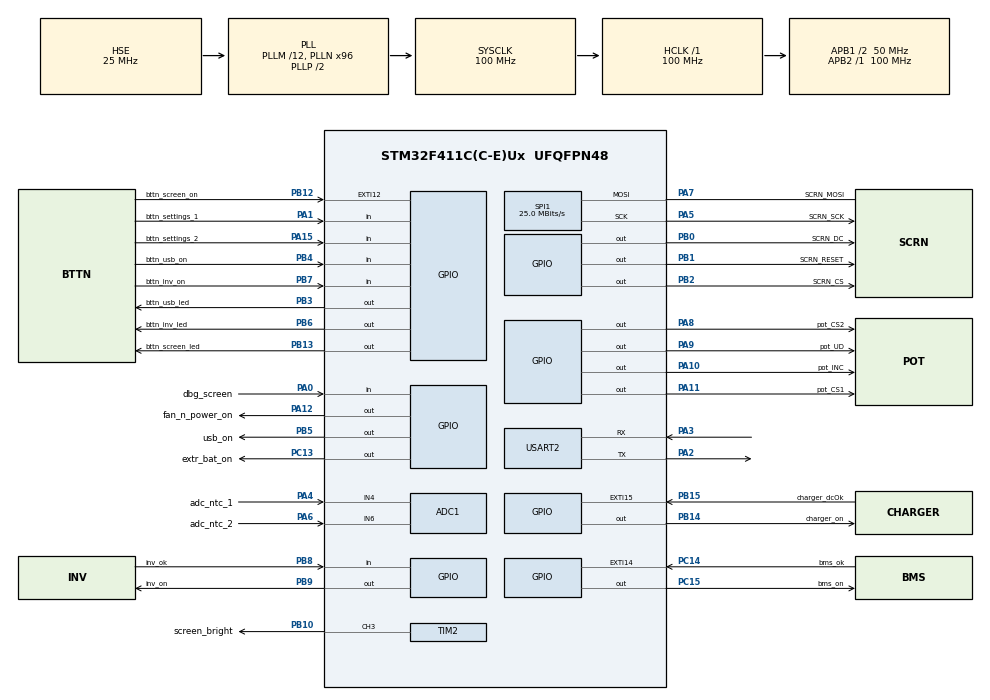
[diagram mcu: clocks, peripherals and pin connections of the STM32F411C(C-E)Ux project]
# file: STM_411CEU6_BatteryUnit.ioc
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ADC1.Channel-0\#ChannelRegularConversion=ADC_CHANNEL_4
ADC1.NbrOfConversionFlag=1
ADC1.Rank-0\#ChannelRegularConversion=1
ADC1.SamplingTime-0\#ChannelRegularConversion=ADC_SAMPLETIME_3CYCLES
ADC1.master=1
Dma.Request0=SPI1_TX
Dma.SPI1_TX.0.Direction=DMA_MEMORY_TO_PERIPH
Dma.SPI1_TX.0.FIFOMode=DMA_FIFOMODE_ENABLE
Dma.SPI1_TX.0.FIFOThreshold=DMA_FIFO_THRESHOLD_FULL
Dma.SPI1_TX.0.Instance=DMA2_Stream2
Dma.SPI1_TX.0.MemBurst=DMA_MBURST_SINGLE
Dma.SPI1_TX.0.MemDataAlignment=DMA_MDATAALIGN_BYTE
Dma.SPI1_TX.0.MemInc=DMA_MINC_ENABLE
Dma.SPI1_TX.0.Mode=DMA_NORMAL
Dma.SPI1_TX.0.PeriphBurst=DMA_PBURST_SINGLE
Dma.SPI1_TX.0.PeriphDataAlignment=DMA_PDATAALIGN_BYTE
Dma.SPI1_TX.0.PeriphInc=DMA_PINC_DISABLE
Dma.SPI1_TX.0.Priority=DMA_PRIORITY_MEDIUM
FREERTOS.Tasks01=defaultTask,24,1024,StartDefaultTask,Default,NULL,Dynamic,NULL,NULL;GUI_Task,24,2560,StartGUITask,Default,NULL,Dynamic,NULL,NULL
FREERTOS.configUSE_NEWLIB_REENTRANT=1
FREERTOS.configUSE_TICKLESS_IDLE=1
Mcu.Family=STM32F4
Mcu.Name=STM32F411C(C-E)Ux
Mcu.Package=UFQFPN48
NVIC.DMA2_Stream2_IRQn=true\:5\:0\:true\:false\:true\:true\:false\:true\:true
NVIC.EXTI15_10_IRQn=true\:5\:0\:false\:false\:true\:true\:true\:true\:true
NVIC.PriorityGroup=NVIC_PRIORITYGROUP_4
NVIC.RCC_IRQn=true\:5\:0\:true\:false\:true\:true\:true\:false\:true
NVIC.RTC_Alarm_IRQn=true\:5\:0\:false\:false\:true\:true\:true\:true\:true
NVIC.SPI1_IRQn=true\:5\:0\:false\:false\:true\:true\:true\:true\:true
NVIC.TIM1_UP_TIM10_IRQn=true\:15\:0\:false\:false\:true\:false\:false\:true\:true
NVIC.TIM4_IRQn=true\:5\:0\:false\:false\:true\:true\:true\:true\:true
NVIC.TimeBase=TIM1_UP_TIM10_IRQn
NVIC.TimeBaseIP=TIM1
NVIC.USART2_IRQn=true\:2\:0\:true\:false\:true\:false\:true\:true\:true
PA0-WKUP.GPIO_Label=dbg_screen
PA0-WKUP.GPIO_PuPd=GPIO_PULLUP
PA0-WKUP.Signal=GPIO_Input
PA1.GPIO_Label=bttn_settings_1
PA1.GPIO_PuPd=GPIO_PULLUP
PA1.Signal=GPIO_Input
PA10.GPIO_Label=pot_INC
PA10.GPIO_ModeDefaultOutputPP=GPIO_MODE_OUTPUT_PP
PA10.GPIO_PuPd=GPIO_PULLDOWN
PA10.PinState=GPIO_PIN_SET
PA10.Signal=GPIO_Output
PA11.GPIO_Label=pot_CS1
PA11.GPIO_PuPd=GPIO_PULLDOWN
PA11.GPIO_Speed=GPIO_SPEED_FREQ_MEDIUM
PA11.PinState=GPIO_PIN_SET
PA11.Signal=GPIO_Output
PA12.GPIO_Label=fan_n_power_on
PA12.GPIO_PuPd=GPIO_PULLDOWN
PA12.Signal=GPIO_Output
PA13.Mode=Serial_Wire
PA13.Signal=SYS_JTMS-SWDIO
PA14.Mode=Serial_Wire
PA14.Signal=SYS_JTCK-SWCLK
PA15.GPIO_Label=bttn_settings_2
PA15.GPIO_PuPd=GPIO_PULLUP
PA15.Signal=GPIO_Input
PA2.Mode=Asynchronous
PA2.Signal=USART2_TX
PA3.Mode=Asynchronous
PA3.Signal=USART2_RX
PA4.GPIO_Label=adc_ntc_1
PA4.Signal=ADCx_IN4
PA5.GPIO_Label=SCRN_SCK
PA5.Mode=Simplex_Bidirectional_Master
PA5.Signal=SPI1_SCK
PA6.GPIO_Label=adc_ntc_2
PA6.Signal=ADCx_IN6
PA7.GPIO_Label=SCRN_MOSI
PA7.Mode=Simplex_Bidirectional_Master
PA7.Signal=SPI1_MOSI
PA8.GPIO_Label=pot_CS2
PA8.GPIO_PuPd=GPIO_PULLDOWN
PA8.GPIO_Speed=GPIO_SPEED_FREQ_MEDIUM
PA8.PinState=GPIO_PIN_SET
PA8.Signal=GPIO_Output
PA9.GPIO_Label=pot_UD
PA9.GPIO_PuPd=GPIO_PULLDOWN
PA9.GPIO_Speed=GPIO_SPEED_FREQ_MEDIUM
PA9.Signal=GPIO_Output
PB0.GPIO_Label=SCRN_DC
PB0.GPIO_PuPd=GPIO_PULLDOWN
PB0.GPIO_Speed=GPIO_SPEED_FREQ_HIGH
PB0.Signal=GPIO_Output
PB1.GPIO_Label=SCRN_RESET
PB1.GPIO_PuPd=GPIO_PULLDOWN
PB1.GPIO_Speed=GPIO_SPEED_FREQ_HIGH
PB1.Signal=GPIO_Output
PB10.GPIO_Label=screen_bright
PB10.Signal=S_TIM2_CH3
PB12.GPIO_Label=bttn_screen_on
PB12.GPIO_PuPd=GPIO_PULLUP
PB12.Signal=GPXTI12
PB13.GPIO_Label=bttn_screen_led
PB13.GPIO_PuPd=GPIO_PULLDOWN
PB13.Signal=GPIO_Output
PB14.GPIO_Label=charger_on
PB14.GPIO_PuPd=GPIO_PULLUP
PB14.PinState=GPIO_PIN_SET
PB14.Signal=GPIO_Output
PB15.GPIO_Label=charger_dcOk
PB15.GPIO_ModeDefaultEXTI=GPIO_MODE_IT_FALLING
PB15.GPIO_PuPd=GPIO_PULLUP
PB15.Signal=GPXTI15
PB2.GPIO_Label=SCRN_CS
PB2.GPIO_PuPd=GPIO_PULLDOWN
PB2.GPIO_Speed=GPIO_SPEED_FREQ_HIGH
PB2.Signal=GPIO_Output
PB3.GPIO_Label=bttn_usb_led
PB3.GPIO_PuPd=GPIO_PULLDOWN
PB3.Signal=GPIO_Output
PB4.GPIO_Label=bttn_usb_on
PB4.GPIO_PuPd=GPIO_PULLUP
PB4.Signal=GPIO_Input
PB5.GPIO_Label=usb_on
PB5.GPIO_PuPd=GPIO_PULLDOWN
PB5.Signal=GPIO_Output
PB6.GPIO_Label=bttn_inv_led
PB6.GPIO_PuPd=GPIO_PULLDOWN
PB6.Signal=GPIO_Output
PB7.GPIO_Label=bttn_inv_on
PB7.GPIO_PuPd=GPIO_PULLUP
PB7.Signal=GPIO_Input
PB8.GPIO_Label=inv_ok
PB8.GPIO_PuPd=GPIO_PULLDOWN
PB8.Signal=GPIO_Input
PB9.GPIO_Label=inv_on
PB9.GPIO_PuPd=GPIO_PULLDOWN
PB9.Signal=GPIO_Output
PC13-ANTI_TAMP.GPIO_Label=extr_bat_on
PC13-ANTI_TAMP.PinState=GPIO_PIN_SET
PC13-ANTI_TAMP.Signal=GPIO_Output
PC14-OSC32_IN.GPIO_Label=bms_ok
PC14-OSC32_IN.GPIO_ModeDefaultEXTI=GPIO_MODE_IT_FALLING
PC14-OSC32_IN.GPIO_PuPd=GPIO_PULLUP
PC14-OSC32_IN.Signal=GPXTI14
PC15-OSC32_OUT.GPIO_Label=bms_on
PC15-OSC32_OUT.GPIO_PuPd=GPIO_PULLDOWN
PC15-OSC32_OUT.Signal=GPIO_Output
PH0\ -\ OSC_IN.Mode=HSE-External-Oscillator
PH0\ -\ OSC_IN.Signal=RCC_OSC_IN
PH1\ -\ OSC_OUT.Mode=HSE-External-Oscillator
PH1\ -\ OSC_OUT.Signal=RCC_OSC_OUT
ProjectManager.HeapSize=0x200
ProjectManager.StackSize=0x400
ProjectManager.TargetToolchain=STM32CubeIDE
RCC.48MHZClocksFreq_Value=50000000
RCC.AHBFreq_Value=100000000
RCC.APB1CLKDivider=RCC_HCLK_DIV2
RCC.APB1Freq_Value=50000000
RCC.APB1TimFreq_Value=100000000
RCC.APB2Freq_Value=100000000
RCC.APB2TimFreq_Value=100000000
RCC.CortexFreq_Value=100000000
RCC.HCLKFreq_Value=100000000
RCC.HSE_Timout=60000
RCC.HSE_VALUE=25000000
RCC.HSI_VALUE=16000000
RCC.LSE_VALUE=32768
RCC.PLLM=12
RCC.PLLN=96
RCC.PLLSourceVirtual=RCC_PLLSOURCE_HSE
RCC.RCC_RTC_Clock_Source=RCC_RTCCLKSOURCE_LSI
RCC.RCC_RTC_Clock_SourceVirtual=RCC_RTCCLKSOURCE_LSI
RCC.SYSCLKFreq_VALUE=100000000
RCC.SYSCLKSource=RCC_SYSCLKSOURCE_PLLCLK
RCC.VCOOutputFreq_Value=200000000
RTC.Alarm=RTC_ALARM_A
RTC.AlarmDateWeekDay=22
RTC.Date=22
RTC.Format=RTC_FORMAT_BIN
RTC.Hours=0
RTC.Hours_A=0
RTC.Minutes=0
RTC.Minutes_A=0
RTC.Month=RTC_MONTH_APRIL
RTC.Seconds=0
RTC.Seconds_A=20
RTC.Year=24
SH.ADCx_IN4.0=ADC1_IN4,IN4
SH.ADCx_IN6.0=ADC1_IN6,IN6
SH.S_TIM2_CH3.0=TIM2_CH3,PWM Generation3 CH3
SPI1.BaudRatePrescaler=SPI_BAUDRATEPRESCALER_4
SPI1.CRCCalculation=SPI_CRCCALCULATION_DISABLE
SPI1.CalculateBaudRate=25.0 MBits/s
SPI1.Direction=SPI_DIRECTION_1LINE
SPI1.Mode=SPI_MODE_MASTER
SPI1.VirtualType=VM_MASTER
STMicroelectronics.X-CUBE-TOUCHGFX.4.24.1.ApplicationCcGraphicsJjApplication=TouchGFXOoGenerator
STMicroelectronics.X-CUBE-TOUCHGFX.4.24.1.tgfx_block_size=1920
STMicroelectronics.X-CUBE-TOUCHGFX.4.24.1.tgfx_buffering_strategy=Partial
STMicroelectronics.X-CUBE-TOUCHGFX.4.24.1.tgfx_custom_height=240
STMicroelectronics.X-CUBE-TOUCHGFX.4.24.1.tgfx_custom_width=320
STMicroelectronics.X-CUBE-TOUCHGFX.4.24.1.tgfx_oswrapper=CMSIS V2
STMicroelectronics.X-CUBE-TOUCHGFX.4.24.1_IsPackSelfContextualization=true
TIM2.Channel-PWM\ Generation3\ CH3=TIM_CHANNEL_3
TIM2.Period=999
TIM2.Prescaler=99
TIM4.Period=15
TIM4.Prescaler=44999
USART2.VirtualMode=VM_ASYNC
VP_CRC_VS_CRC.Mode=CRC_Activate
VP_FREERTOS_VS_CMSIS_V2.Mode=CMSIS_V2
VP_RTC_VS_RTC_Activate.Mode=RTC_Enabled
VP_RTC_VS_RTC_Alarm_A_Intern.Mode=Alarm A
VP_RTC_VS_RTC_Calendar.Mode=RTC_Calendar
VP_STMicroelectronics.X-CUBE-TOUCHGFX_VS_GraphicsJjApplication_4.24.1.Mode=GraphicsJjApplication
VP_SYS_VS_tim1.Mode=TIM1
VP_TIM2_VS_ClockSourceINT.Mode=Internal
VP_TIM4_VS_ClockSourceINT.Mode=Internal
board=custom

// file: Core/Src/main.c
/* USER CODE BEGIN Header */
/**
  ******************************************************************************
  * @file           : main.c
  * @brief          : Main program body
  ******************************************************************************
  * @attention
  *
  * Copyright (c) 2024 STMicroelectronics.
  * All rights reserved.
  *
  * This software is licensed under terms that can be found in the LICENSE file
  * in the root directory of this software component.
  * If no LICENSE file comes with this software, it is provided AS-IS.
  *
  ******************************************************************************
  */
/* USER CODE END Header */
#include "main.h"
#include "cmsis_os.h"
#include "app_touchgfx.h"

/* USER CODE BEGIN Includes */
#include <program.h>
/* USER CODE END Includes */

ADC_HandleTypeDef hadc1;

CRC_HandleTypeDef hcrc;

RTC_HandleTypeDef hrtc;

SPI_HandleTypeDef hspi1;
DMA_HandleTypeDef hdma_spi1_tx;

TIM_HandleTypeDef htim2;
TIM_HandleTypeDef htim4;

UART_HandleTypeDef huart2;

/* Definitions for defaultTask */
osThreadId_t defaultTaskHandle;
const osThreadAttr_t defaultTask_attributes = {
  .name = "defaultTask",
  .stack_size = 1024 * 4,
  .priority = (osPriority_t) osPriorityNormal,
};
/* Definitions for GUI_Task */
osThreadId_t GUI_TaskHandle;
const osThreadAttr_t GUI_Task_attributes = {
  .name = "GUI_Task",
  .stack_size = 2560 * 4,
  .priority = (osPriority_t) osPriorityNormal,
};

void SystemClock_Config(void);
static void MX_GPIO_Init(void);
static void MX_DMA_Init(void);
static void MX_SPI1_Init(void);
static void MX_CRC_Init(void);
static void MX_TIM4_Init(void);
static void MX_USART2_UART_Init(void);
static void MX_RTC_Init(void);
static void MX_TIM2_Init(void);
static void MX_ADC1_Init(void);
void StartDefaultTask(void *argument);
void StartGUITask(void *argument);

int main(void)
{

  /* MCU Configuration--------------------------------------------------------*/

  /* Reset of all peripherals, Initializes the Flash interface and the Systick. */
  HAL_Init();

  /* Configure the system clock */
  SystemClock_Config();

  /* Initialize all configured peripherals */
  MX_GPIO_Init();
  MX_DMA_Init();
  MX_SPI1_Init();
  MX_CRC_Init();
  MX_TIM4_Init();
  MX_USART2_UART_Init();
  MX_RTC_Init();
  MX_TIM2_Init();
  MX_ADC1_Init();
  MX_TouchGFX_Init();
  /* Call PreOsInit function */
  MX_TouchGFX_PreOSInit();
  /* USER CODE BEGIN 2 */
//  Program_Process();
  /* USER CODE END 2 */

  /* Init scheduler */
  osKernelInitialize();

  /* Create the thread(s) */
  /* creation of defaultTask */
  defaultTaskHandle = osThreadNew(StartDefaultTask, NULL, &defaultTask_attributes);

  /* creation of GUI_Task */
  GUI_TaskHandle = osThreadNew(StartGUITask, NULL, &GUI_Task_attributes);

  /* Start scheduler */
  osKernelStart();

  /* We should never get here as control is now taken by the scheduler */

  /* Infinite loop */
  while (1)
  {

  }
}

void SystemClock_Config(void)
{
  RCC_OscInitTypeDef RCC_OscInitStruct = {0};
  RCC_ClkInitTypeDef RCC_ClkInitStruct = {0};

  /** Configure the main internal regulator output voltage
  */
  __HAL_RCC_PWR_CLK_ENABLE();
  __HAL_PWR_VOLTAGESCALING_CONFIG(PWR_REGULATOR_VOLTAGE_SCALE1);

  /** Initializes the RCC Oscillators according to the specified parameters
  * in the RCC_OscInitTypeDef structure.
  */
  RCC_OscInitStruct.OscillatorType = RCC_OSCILLATORTYPE_LSI|RCC_OSCILLATORTYPE_HSE;
  RCC_OscInitStruct.HSEState = RCC_HSE_ON;
  RCC_OscInitStruct.LSIState = RCC_LSI_ON;
  RCC_OscInitStruct.PLL.PLLState = RCC_PLL_ON;
  RCC_OscInitStruct.PLL.PLLSource = RCC_PLLSOURCE_HSE;
  RCC_OscInitStruct.PLL.PLLM = 12;
  RCC_OscInitStruct.PLL.PLLN = 96;
  RCC_OscInitStruct.PLL.PLLP = RCC_PLLP_DIV2;
  RCC_OscInitStruct.PLL.PLLQ = 4;
  if (HAL_RCC_OscConfig(&RCC_OscInitStruct) != HAL_OK)
  {
    Error_Handler();
  }

  /** Initializes the CPU, AHB and APB buses clocks
  */
  RCC_ClkInitStruct.ClockType = RCC_CLOCKTYPE_HCLK|RCC_CLOCKTYPE_SYSCLK
                              |RCC_CLOCKTYPE_PCLK1|RCC_CLOCKTYPE_PCLK2;
  RCC_ClkInitStruct.SYSCLKSource = RCC_SYSCLKSOURCE_PLLCLK;
  RCC_ClkInitStruct.AHBCLKDivider = RCC_SYSCLK_DIV1;
  RCC_ClkInitStruct.APB1CLKDivider = RCC_HCLK_DIV2;
  RCC_ClkInitStruct.APB2CLKDivider = RCC_HCLK_DIV1;

  if (HAL_RCC_ClockConfig(&RCC_ClkInitStruct, FLASH_LATENCY_3) != HAL_OK)
  {
    Error_Handler();
  }
}

static void MX_ADC1_Init(void)
{

  ADC_ChannelConfTypeDef sConfig = {0};

  /** Configure the global features of the ADC (Clock, Resolution, Data Alignment and number of conversion)
  */
  hadc1.Instance = ADC1;
  hadc1.Init.ClockPrescaler = ADC_CLOCK_SYNC_PCLK_DIV4;
  hadc1.Init.Resolution = ADC_RESOLUTION_12B;
  hadc1.Init.ScanConvMode = DISABLE;
  hadc1.Init.ContinuousConvMode = DISABLE;
  hadc1.Init.DiscontinuousConvMode = DISABLE;
  hadc1.Init.ExternalTrigConvEdge = ADC_EXTERNALTRIGCONVEDGE_NONE;
  hadc1.Init.ExternalTrigConv = ADC_SOFTWARE_START;
  hadc1.Init.DataAlign = ADC_DATAALIGN_RIGHT;
  hadc1.Init.NbrOfConversion = 1;
  hadc1.Init.DMAContinuousRequests = DISABLE;
  hadc1.Init.EOCSelection = ADC_EOC_SINGLE_CONV;
  if (HAL_ADC_Init(&hadc1) != HAL_OK)
  {
    Error_Handler();
  }

  /** Configure for the selected ADC regular channel its corresponding rank in the sequencer and its sample time.
  */
  sConfig.Channel = ADC_CHANNEL_4;
  sConfig.Rank = 1;
  sConfig.SamplingTime = ADC_SAMPLETIME_3CYCLES;
  if (HAL_ADC_ConfigChannel(&hadc1, &sConfig) != HAL_OK)
  {
    Error_Handler();
  }

}

static void MX_CRC_Init(void)
{

  hcrc.Instance = CRC;
  if (HAL_CRC_Init(&hcrc) != HAL_OK)
  {
    Error_Handler();
  }

}

static void MX_RTC_Init(void)
{

  RTC_TimeTypeDef sTime = {0};
  RTC_DateTypeDef sDate = {0};
  RTC_AlarmTypeDef sAlarm = {0};

  /** Initialize RTC Only
  */
  hrtc.Instance = RTC;
  hrtc.Init.HourFormat = RTC_HOURFORMAT_24;
  hrtc.Init.AsynchPrediv = 127;
  hrtc.Init.SynchPrediv = 255;
  hrtc.Init.OutPut = RTC_OUTPUT_DISABLE;
  hrtc.Init.OutPutPolarity = RTC_OUTPUT_POLARITY_HIGH;
  hrtc.Init.OutPutType = RTC_OUTPUT_TYPE_OPENDRAIN;
  if (HAL_RTC_Init(&hrtc) != HAL_OK)
  {
    Error_Handler();
  }

  /* USER CODE BEGIN Check_RTC_BKUP */
  if (Check_RTC_Backup(&hrtc)) {
	  return;
  }
  /* USER CODE END Check_RTC_BKUP */

  /** Initialize RTC and set the Time and Date
  */
  sTime.Hours = 0;
  sTime.Minutes = 0;
  sTime.Seconds = 0;
  sTime.DayLightSaving = RTC_DAYLIGHTSAVING_NONE;
  sTime.StoreOperation = RTC_STOREOPERATION_RESET;
  if (HAL_RTC_SetTime(&hrtc, &sTime, RTC_FORMAT_BIN) != HAL_OK)
  {
    Error_Handler();
  }
  sDate.WeekDay = RTC_WEEKDAY_MONDAY;
  sDate.Month = RTC_MONTH_APRIL;
  sDate.Date = 22;
  sDate.Year = 24;

  if (HAL_RTC_SetDate(&hrtc, &sDate, RTC_FORMAT_BIN) != HAL_OK)
  {
    Error_Handler();
  }

  /** Enable the Alarm A
  */
  sAlarm.AlarmTime.Hours = 0;
  sAlarm.AlarmTime.Minutes = 0;
  sAlarm.AlarmTime.Seconds = 20;
  sAlarm.AlarmTime.SubSeconds = 0;
  sAlarm.AlarmTime.DayLightSaving = RTC_DAYLIGHTSAVING_NONE;
  sAlarm.AlarmTime.StoreOperation = RTC_STOREOPERATION_RESET;
  sAlarm.AlarmMask = RTC_ALARMMASK_NONE;
  sAlarm.AlarmSubSecondMask = RTC_ALARMSUBSECONDMASK_ALL;
  sAlarm.AlarmDateWeekDaySel = RTC_ALARMDATEWEEKDAYSEL_DATE;
  sAlarm.AlarmDateWeekDay = 22;
  sAlarm.Alarm = RTC_ALARM_A;
  if (HAL_RTC_SetAlarm_IT(&hrtc, &sAlarm, RTC_FORMAT_BIN) != HAL_OK)
  {
    Error_Handler();
  }
  /* USER CODE BEGIN RTC_Init 2 */
  RTC_Backup(&hrtc, &sAlarm);
  /* USER CODE END RTC_Init 2 */

}

static void MX_SPI1_Init(void)
{

  /* SPI1 parameter configuration*/
  hspi1.Instance = SPI1;
  hspi1.Init.Mode = SPI_MODE_MASTER;
  hspi1.Init.Direction = SPI_DIRECTION_1LINE;
  hspi1.Init.DataSize = SPI_DATASIZE_8BIT;
  hspi1.Init.CLKPolarity = SPI_POLARITY_LOW;
  hspi1.Init.CLKPhase = SPI_PHASE_1EDGE;
  hspi1.Init.NSS = SPI_NSS_SOFT;
  hspi1.Init.BaudRatePrescaler = SPI_BAUDRATEPRESCALER_4;
  hspi1.Init.FirstBit = SPI_FIRSTBIT_MSB;
  hspi1.Init.TIMode = SPI_TIMODE_DISABLE;
  hspi1.Init.CRCCalculation = SPI_CRCCALCULATION_DISABLE;
  hspi1.Init.CRCPolynomial = 10;
  if (HAL_SPI_Init(&hspi1) != HAL_OK)
  {
    Error_Handler();
  }

}

static void MX_TIM2_Init(void)
{

  TIM_ClockConfigTypeDef sClockSourceConfig = {0};
  TIM_MasterConfigTypeDef sMasterConfig = {0};
  TIM_OC_InitTypeDef sConfigOC = {0};

  htim2.Instance = TIM2;
  htim2.Init.Prescaler = 99;
  htim2.Init.CounterMode = TIM_COUNTERMODE_UP;
  htim2.Init.Period = 999;
  htim2.Init.ClockDivision = TIM_CLOCKDIVISION_DIV1;
  htim2.Init.AutoReloadPreload = TIM_AUTORELOAD_PRELOAD_DISABLE;
  if (HAL_TIM_Base_Init(&htim2) != HAL_OK)
  {
    Error_Handler();
  }
  sClockSourceConfig.ClockSource = TIM_CLOCKSOURCE_INTERNAL;
  if (HAL_TIM_ConfigClockSource(&htim2, &sClockSourceConfig) != HAL_OK)
  {
    Error_Handler();
  }
  if (HAL_TIM_PWM_Init(&htim2) != HAL_OK)
  {
    Error_Handler();
  }
  sMasterConfig.MasterOutputTrigger = TIM_TRGO_RESET;
  sMasterConfig.MasterSlaveMode = TIM_MASTERSLAVEMODE_DISABLE;
  if (HAL_TIMEx_MasterConfigSynchronization(&htim2, &sMasterConfig) != HAL_OK)
  {
    Error_Handler();
  }
  sConfigOC.OCMode = TIM_OCMODE_PWM1;
  sConfigOC.Pulse = 0;
  sConfigOC.OCPolarity = TIM_OCPOLARITY_HIGH;
  sConfigOC.OCFastMode = TIM_OCFAST_DISABLE;
  if (HAL_TIM_PWM_ConfigChannel(&htim2, &sConfigOC, TIM_CHANNEL_3) != HAL_OK)
  {
    Error_Handler();
  }
  HAL_TIM_MspPostInit(&htim2);

}

static void MX_TIM4_Init(void)
{

  TIM_ClockConfigTypeDef sClockSourceConfig = {0};
  TIM_MasterConfigTypeDef sMasterConfig = {0};

  htim4.Instance = TIM4;
  htim4.Init.Prescaler = 44999;
  htim4.Init.CounterMode = TIM_COUNTERMODE_UP;
  htim4.Init.Period = 15;
  htim4.Init.ClockDivision = TIM_CLOCKDIVISION_DIV1;
  htim4.Init.AutoReloadPreload = TIM_AUTORELOAD_PRELOAD_DISABLE;
  if (HAL_TIM_Base_Init(&htim4) != HAL_OK)
  {
    Error_Handler();
  }
  sClockSourceConfig.ClockSource = TIM_CLOCKSOURCE_INTERNAL;
  if (HAL_TIM_ConfigClockSource(&htim4, &sClockSourceConfig) != HAL_OK)
  {
    Error_Handler();
  }
  sMasterConfig.MasterOutputTrigger = TIM_TRGO_RESET;
  sMasterConfig.MasterSlaveMode = TIM_MASTERSLAVEMODE_DISABLE;
  if (HAL_TIMEx_MasterConfigSynchronization(&htim4, &sMasterConfig) != HAL_OK)
  {
    Error_Handler();
  }

}

static void MX_USART2_UART_Init(void)
{

  huart2.Instance = USART2;
  huart2.Init.BaudRate = 115200;
  huart2.Init.WordLength = UART_WORDLENGTH_8B;
  huart2.Init.StopBits = UART_STOPBITS_1;
  huart2.Init.Parity = UART_PARITY_NONE;
  huart2.Init.Mode = UART_MODE_TX_RX;
  huart2.Init.HwFlowCtl = UART_HWCONTROL_NONE;
  huart2.Init.OverSampling = UART_OVERSAMPLING_16;
  if (HAL_UART_Init(&huart2) != HAL_OK)
  {
    Error_Handler();
  }

}

static void MX_DMA_Init(void)
{

  /* DMA controller clock enable */
  __HAL_RCC_DMA2_CLK_ENABLE();

  /* DMA interrupt init */
  /* DMA2_Stream2_IRQn interrupt configuration */
  HAL_NVIC_SetPriority(DMA2_Stream2_IRQn, 5, 0);
  HAL_NVIC_EnableIRQ(DMA2_Stream2_IRQn);

}

static void MX_GPIO_Init(void)
{
  GPIO_InitTypeDef GPIO_InitStruct = {0};

  /* GPIO Ports Clock Enable */
  __HAL_RCC_GPIOC_CLK_ENABLE();
  __HAL_RCC_GPIOH_CLK_ENABLE();
  __HAL_RCC_GPIOA_CLK_ENABLE();
  __HAL_RCC_GPIOB_CLK_ENABLE();

  /*Configure GPIO pin Output Level */
  HAL_GPIO_WritePin(extr_bat_on_GPIO_Port, extr_bat_on_Pin, GPIO_PIN_SET);

  /*Configure GPIO pin Output Level */
  HAL_GPIO_WritePin(bms_on_GPIO_Port, bms_on_Pin, GPIO_PIN_RESET);

  /*Configure GPIO pin Output Level */
  HAL_GPIO_WritePin(GPIOB, SCRN_DC_Pin|SCRN_RESET_Pin|SCRN_CS_Pin|bttn_screen_led_Pin
                          |bttn_usb_led_Pin|usb_on_Pin|bttn_inv_led_Pin|inv_on_Pin, GPIO_PIN_RESET);

  /*Configure GPIO pin Output Level */
  HAL_GPIO_WritePin(charger_on_GPIO_Port, charger_on_Pin, GPIO_PIN_SET);

  /*Configure GPIO pin Output Level */
  HAL_GPIO_WritePin(GPIOA, pot_CS2_Pin|pot_INC_Pin|pot_CS1_Pin, GPIO_PIN_SET);

  /*Configure GPIO pin Output Level */
  HAL_GPIO_WritePin(GPIOA, pot_UD_Pin|fan_n_power_on_Pin, GPIO_PIN_RESET);

  /*Configure GPIO pin : extr_bat_on_Pin */
  GPIO_InitStruct.Pin = extr_bat_on_Pin;
  GPIO_InitStruct.Mode = GPIO_MODE_OUTPUT_PP;
  GPIO_InitStruct.Pull = GPIO_NOPULL;
  GPIO_InitStruct.Speed = GPIO_SPEED_FREQ_LOW;
  HAL_GPIO_Init(extr_bat_on_GPIO_Port, &GPIO_InitStruct);

  /*Configure GPIO pin : bms_ok_Pin */
  GPIO_InitStruct.Pin = bms_ok_Pin;
  GPIO_InitStruct.Mode = GPIO_MODE_IT_FALLING;
  GPIO_InitStruct.Pull = GPIO_PULLUP;
  HAL_GPIO_Init(bms_ok_GPIO_Port, &GPIO_InitStruct);

  /*Configure GPIO pin : bms_on_Pin */
  GPIO_InitStruct.Pin = bms_on_Pin;
  GPIO_InitStruct.Mode = GPIO_MODE_OUTPUT_PP;
  GPIO_InitStruct.Pull = GPIO_PULLDOWN;
  GPIO_InitStruct.Speed = GPIO_SPEED_FREQ_LOW;
  HAL_GPIO_Init(bms_on_GPIO_Port, &GPIO_InitStruct);

  /*Configure GPIO pins : dbg_screen_Pin bttn_settings_1_Pin bttn_settings_2_Pin */
  GPIO_InitStruct.Pin = dbg_screen_Pin|bttn_settings_1_Pin|bttn_settings_2_Pin;
  GPIO_InitStruct.Mode = GPIO_MODE_INPUT;
  GPIO_InitStruct.Pull = GPIO_PULLUP;
  HAL_GPIO_Init(GPIOA, &GPIO_InitStruct);

  /*Configure GPIO pins : SCRN_DC_Pin SCRN_RESET_Pin SCRN_CS_Pin */
  GPIO_InitStruct.Pin = SCRN_DC_Pin|SCRN_RESET_Pin|SCRN_CS_Pin;
  GPIO_InitStruct.Mode = GPIO_MODE_OUTPUT_PP;
  GPIO_InitStruct.Pull = GPIO_PULLDOWN;
  GPIO_InitStruct.Speed = GPIO_SPEED_FREQ_HIGH;
  HAL_GPIO_Init(GPIOB, &GPIO_InitStruct);

  /*Configure GPIO pin : bttn_screen_on_Pin */
  GPIO_InitStruct.Pin = bttn_screen_on_Pin;
  GPIO_InitStruct.Mode = GPIO_MODE_IT_RISING;
  GPIO_InitStruct.Pull = GPIO_PULLUP;
  HAL_GPIO_Init(bttn_screen_on_GPIO_Port, &GPIO_InitStruct);

  /*Configure GPIO pins : bttn_screen_led_Pin bttn_usb_led_Pin usb_on_Pin bttn_inv_led_Pin
                           inv_on_Pin */
  GPIO_InitStruct.Pin = bttn_screen_led_Pin|bttn_usb_led_Pin|usb_on_Pin|bttn_inv_led_Pin
                          |inv_on_Pin;
  GPIO_InitStruct.Mode = GPIO_MODE_OUTPUT_PP;
  GPIO_InitStruct.Pull = GPIO_PULLDOWN;
  GPIO_InitStruct.Speed = GPIO_SPEED_FREQ_LOW;
  HAL_GPIO_Init(GPIOB, &GPIO_InitStruct);

  /*Configure GPIO pin : charger_on_Pin */
  GPIO_InitStruct.Pin = charger_on_Pin;
  GPIO_InitStruct.Mode = GPIO_MODE_OUTPUT_PP;
  GPIO_InitStruct.Pull = GPIO_PULLUP;
  GPIO_InitStruct.Speed = GPIO_SPEED_FREQ_LOW;
  HAL_GPIO_Init(charger_on_GPIO_Port, &GPIO_InitStruct);

  /*Configure GPIO pin : charger_dcOk_Pin */
  GPIO_InitStruct.Pin = charger_dcOk_Pin;
  GPIO_InitStruct.Mode = GPIO_MODE_IT_FALLING;
  GPIO_InitStruct.Pull = GPIO_PULLUP;
  HAL_GPIO_Init(charger_dcOk_GPIO_Port, &GPIO_InitStruct);

  /*Configure GPIO pins : pot_CS2_Pin pot_UD_Pin pot_CS1_Pin */
  GPIO_InitStruct.Pin = pot_CS2_Pin|pot_UD_Pin|pot_CS1_Pin;
  GPIO_InitStruct.Mode = GPIO_MODE_OUTPUT_PP;
  GPIO_InitStruct.Pull = GPIO_PULLDOWN;
  GPIO_InitStruct.Speed = GPIO_SPEED_FREQ_MEDIUM;
  HAL_GPIO_Init(GPIOA, &GPIO_InitStruct);

  /*Configure GPIO pins : pot_INC_Pin fan_n_power_on_Pin */
  GPIO_InitStruct.Pin = pot_INC_Pin|fan_n_power_on_Pin;
  GPIO_InitStruct.Mode = GPIO_MODE_OUTPUT_PP;
  GPIO_InitStruct.Pull = GPIO_PULLDOWN;
  GPIO_InitStruct.Speed = GPIO_SPEED_FREQ_LOW;
  HAL_GPIO_Init(GPIOA, &GPIO_InitStruct);

  /*Configure GPIO pins : bttn_usb_on_Pin bttn_inv_on_Pin */
  GPIO_InitStruct.Pin = bttn_usb_on_Pin|bttn_inv_on_Pin;
  GPIO_InitStruct.Mode = GPIO_MODE_INPUT;
  GPIO_InitStruct.Pull = GPIO_PULLUP;
  HAL_GPIO_Init(GPIOB, &GPIO_InitStruct);

  /*Configure GPIO pin : inv_ok_Pin */
  GPIO_InitStruct.Pin = inv_ok_Pin;
  GPIO_InitStruct.Mode = GPIO_MODE_INPUT;
  GPIO_InitStruct.Pull = GPIO_PULLDOWN;
  HAL_GPIO_Init(inv_ok_GPIO_Port, &GPIO_InitStruct);

  /* EXTI interrupt init*/
  HAL_NVIC_SetPriority(EXTI15_10_IRQn, 5, 0);
  HAL_NVIC_EnableIRQ(EXTI15_10_IRQn);

}

void StartDefaultTask(void *argument)
{
  /* USER CODE BEGIN 5 */
  /* Infinite loop */
	Program_Process();
  /* USER CODE END 5 */
}

void StartGUITask(void *argument)
{
  /* USER CODE BEGIN StartGUITask */
  /* Infinite loop */
	ILI9341_Init();
	HAL_TIM_PWM_Start(&htim2, TIM_CHANNEL_3);
	HAL_TIM_Base_Start_IT(&htim4);
	TouchGFX_Task(argument);
  /* USER CODE END StartGUITask */
}

void HAL_TIM_PeriodElapsedCallback(TIM_HandleTypeDef *htim)
{
  if (htim->Instance == TIM1)
  {
    HAL_IncTick();
  }
  /* USER CODE BEGIN Callback 1 */
  else if (htim->Instance == TIM4)
  {
      touchgfxSignalVSync();
  }
  /* USER CODE END Callback 1 */
}

void Error_Handler(void)
{
  __disable_irq();
  while (1)
  {
  }
}
